# TLSR826X register map
File version: 0.1
Registers are 8-bit, access not given, no defined reset value unless marked. A register's access mark holds for its fields unless they carry their own. Offsets are from the block's base; [hi:lo] are bit positions; {n}, {i} and the like mark numbered series.

## AUDIO — Auto-generated from section 'audio'
Base 0x00800056
0x00 AUD_CONST 32-bit — Auto-generated from aud_const
0xAA CTRL_EP_PTR — Auto-generated from ctrl_ep_ptr
0xAB CTRL_EP_DAT — Auto-generated from ctrl_ep_dat
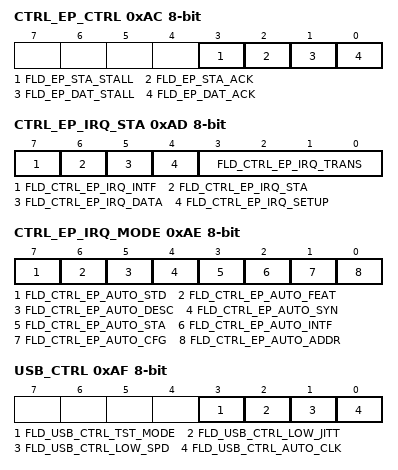
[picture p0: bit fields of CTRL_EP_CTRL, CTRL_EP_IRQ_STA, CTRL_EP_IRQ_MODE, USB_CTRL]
0xAC CTRL_EP_CTRL — Auto-generated from ctrl_ep_ctrl
  [3] FLD_EP_STA_STALL, [2] FLD_EP_STA_ACK, [1] FLD_EP_DAT_STALL, [0] FLD_EP_DAT_ACK
0xAD CTRL_EP_IRQ_STA — Auto-generated from ctrl_ep_irq_sta
  [7] FLD_CTRL_EP_IRQ_INTF, [6] FLD_CTRL_EP_IRQ_STA, [5] FLD_CTRL_EP_IRQ_DATA, [4] FLD_CTRL_EP_IRQ_SETUP, [3:0] FLD_CTRL_EP_IRQ_TRANS
0xAE CTRL_EP_IRQ_MODE — Auto-generated from ctrl_ep_irq_mode
  [7] FLD_CTRL_EP_AUTO_STD, [6] FLD_CTRL_EP_AUTO_FEAT, [5] FLD_CTRL_EP_AUTO_DESC, [4] FLD_CTRL_EP_AUTO_SYN, [3] FLD_CTRL_EP_AUTO_STA, [2] FLD_CTRL_EP_AUTO_INTF, [1] FLD_CTRL_EP_AUTO_CFG, [0] FLD_CTRL_EP_AUTO_ADDR
0xAF USB_CTRL — Auto-generated from usb_ctrl
  [3] FLD_USB_CTRL_TST_MODE, [2] FLD_USB_CTRL_LOW_JITT, [1] FLD_USB_CTRL_LOW_SPD, [0] FLD_USB_CTRL_AUTO_CLK
0xB0 USB_CYC_CALI 16-bit — Auto-generated from usb_cyc_cali
0xB4 USB_MDEV — Auto-generated from usb_mdev
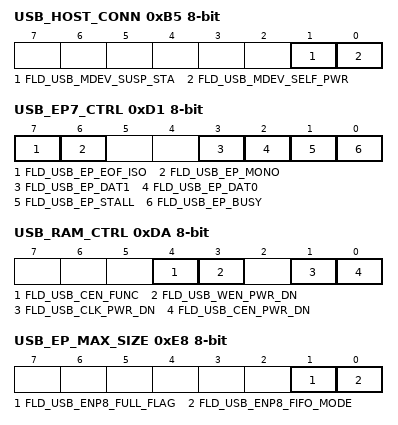
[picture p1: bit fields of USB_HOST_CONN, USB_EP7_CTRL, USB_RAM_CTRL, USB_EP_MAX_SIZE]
0xB5 USB_HOST_CONN — Auto-generated from usb_host_conn
  [1] FLD_USB_MDEV_SUSP_STA, [0] FLD_USB_MDEV_SELF_PWR
0xB6 USB_SUPS_CYC_CALI — Auto-generated from usb_sups_cyc_cali
0xB7 USB_INTF_ALT — Auto-generated from usb_intf_alt
0xBA USB_EP8123_PTR 32-bit — Auto-generated from usb_ep8123_ptr; aliases: USB_EP8_PTR
{0xBA+i} USB_EP{i}_PTR (i=1..3) — Auto-generated from usb_ep{i}_ptr
0xBE USB_EP4567_PTR 32-bit — Auto-generated from usb_ep4567_ptr; aliases: USB_EP4_PTR
{0xBA+i} USB_EP{i}_PTR (i=5..7) — Auto-generated from usb_ep{i}_ptr
0xC2 USB_EP8123_DAT 32-bit — Auto-generated from usb_ep8123_dat; aliases: USB_EP8_DAT
{0xC2+i} USB_EP{i}_DAT (i=1..3) — Auto-generated from usb_ep{i}_dat
0xC6 USB_EP4567_DAT 32-bit — Auto-generated from usb_ep4567_dat; aliases: USB_EP4_DAT
{0xC2+i} USB_EP{i}_DAT (i=5..7) — Auto-generated from usb_ep{i}_dat
0xCA USB_EP8_CTRL — Auto-generated from usb_ep8_ctrl
{0xCA+i} USB_EP{i}_CTRL (i=1..6) — Auto-generated from usb_ep{i}_ctrl
0xD1 USB_EP7_CTRL — Auto-generated from usb_ep7_ctrl
  [7] FLD_USB_EP_EOF_ISO, [6] FLD_USB_EP_MONO, [3] FLD_USB_EP_DAT1, [2] FLD_USB_EP_DAT0, [1] FLD_USB_EP_STALL, [0] FLD_USB_EP_BUSY
0xD2 USB_EP8123_BUF_ADDR 32-bit — Auto-generated from usb_ep8123_buf_addr; aliases: USB_EP8_BUF_ADDR
{0xD2+i} USB_EP{i}_BUF_ADDR (i=1..3) — Auto-generated from usb_ep{i}_buf_addr
0xD6 USB_EP4567_BUF_ADDR 32-bit — Auto-generated from usb_ep4567_buf_addr; aliases: USB_EP4_BUF_ADDR
{0xD2+i} USB_EP{i}_BUF_ADDR (i=5..7) — Auto-generated from usb_ep{i}_buf_addr
0xDA USB_RAM_CTRL — Auto-generated from usb_ram_ctrl
  [4] FLD_USB_CEN_FUNC, [3] FLD_USB_WEN_PWR_DN, [1] FLD_USB_CLK_PWR_DN, [0] FLD_USB_CEN_PWR_DN
0xE2 USB_ISO_MODE — Auto-generated from usb_iso_mode
0xE3 USB_IRQ — Auto-generated from usb_irq
0xE4 USB_MASK — Auto-generated from usb_mask
0xE5 USB_EP8_SEND_MAX — Auto-generated from usb_ep8_send_max
0xE6 USB_EP8_SEND_THRES — Auto-generated from usb_ep8_send_thres
0xE7 USB_EP8_FIFO_MODE — Auto-generated from usb_ep8_fifo_mode
0xE8 USB_EP_MAX_SIZE — Auto-generated from usb_ep_max_size
  [1] FLD_USB_ENP8_FULL_FLAG, [0] FLD_USB_ENP8_FIFO_MODE
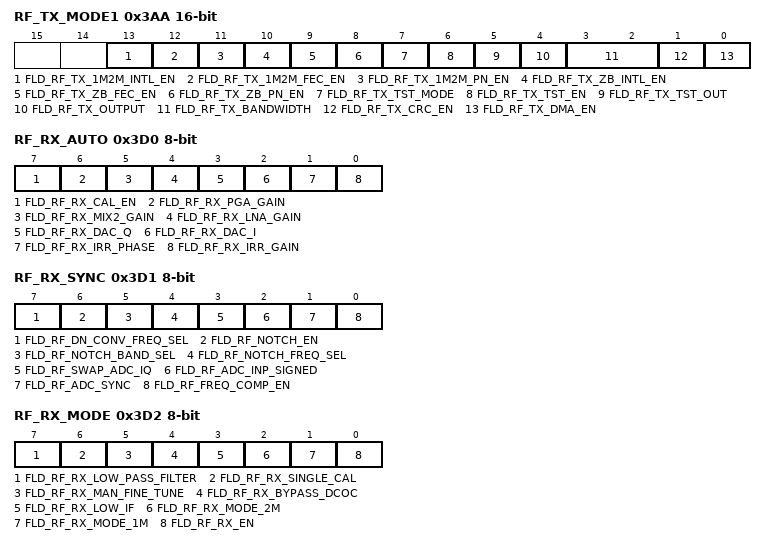
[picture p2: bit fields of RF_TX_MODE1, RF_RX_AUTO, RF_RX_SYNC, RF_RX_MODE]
0x3AA RF_TX_MODE1 16-bit — Auto-generated from rf_tx_mode1; aliases: RF_TX_MODE
  [13] FLD_RF_TX_1M2M_INTL_EN, [12] FLD_RF_TX_1M2M_FEC_EN, [11] FLD_RF_TX_1M2M_PN_EN, [10] FLD_RF_TX_ZB_INTL_EN, [9] FLD_RF_TX_ZB_FEC_EN, [8] FLD_RF_TX_ZB_PN_EN, [7] FLD_RF_TX_TST_MODE, [6] FLD_RF_TX_TST_EN, [5] FLD_RF_TX_TST_OUT, [4] FLD_RF_TX_OUTPUT, [3:2] FLD_RF_TX_BANDWIDTH, [1] FLD_RF_TX_CRC_EN, [0] FLD_RF_TX_DMA_EN
0x3C6 RF_TX_BUF_STA 32-bit — Auto-generated from rf_tx_buf_sta
0x3CC RF_RX_SENSE_THR — Auto-generated from rf_rx_sense_thr
0x3D0 RF_RX_AUTO — Auto-generated from rf_rx_auto
  [7] FLD_RF_RX_CAL_EN, [6] FLD_RF_RX_PGA_GAIN, [5] FLD_RF_RX_MIX2_GAIN, [4] FLD_RF_RX_LNA_GAIN, [3] FLD_RF_RX_DAC_Q, [2] FLD_RF_RX_DAC_I, [1] FLD_RF_RX_IRR_PHASE, [0] FLD_RF_RX_IRR_GAIN
0x3D1 RF_RX_SYNC — Auto-generated from rf_rx_sync
  [7] FLD_RF_DN_CONV_FREQ_SEL, [6] FLD_RF_NOTCH_EN, [5] FLD_RF_NOTCH_BAND_SEL, [4] FLD_RF_NOTCH_FREQ_SEL, [3] FLD_RF_SWAP_ADC_IQ, [2] FLD_RF_ADC_INP_SIGNED, [1] FLD_RF_ADC_SYNC, [0] FLD_RF_FREQ_COMP_EN
0x3D2 RF_RX_MODE — Auto-generated from rf_rx_mode
  [7] FLD_RF_RX_LOW_PASS_FILTER, [6] FLD_RF_RX_SINGLE_CAL, [5] FLD_RF_RX_MAN_FINE_TUNE, [4] FLD_RF_RX_BYPASS_DCOC, [3] FLD_RF_RX_LOW_IF, [2] FLD_RF_RX_MODE_2M, [1] FLD_RF_RX_MODE_1M, [0] FLD_RF_RX_EN
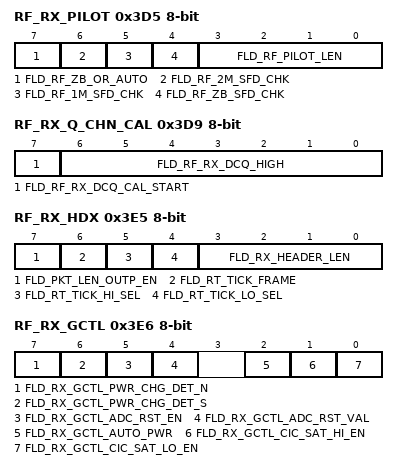
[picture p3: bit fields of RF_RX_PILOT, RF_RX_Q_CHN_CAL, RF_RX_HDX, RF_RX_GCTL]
0x3D5 RF_RX_PILOT — Auto-generated from rf_rx_pilot
  [7] FLD_RF_ZB_OR_AUTO, [6] FLD_RF_2M_SFD_CHK, [5] FLD_RF_1M_SFD_CHK, [4] FLD_RF_ZB_SFD_CHK, [3:0] FLD_RF_PILOT_LEN
0x3D6 RF_RX_CHN_DC 32-bit — Auto-generated from rf_rx_chn_dc
0x3D9 RF_RX_Q_CHN_CAL — Auto-generated from rf_rx_q_chn_cal
  [7] FLD_RF_RX_DCQ_CAL_START, [6:0] FLD_RF_RX_DCQ_HIGH
0x3DE RF_RX_PEL 32-bit — Auto-generated from rf_rx_pel; aliases: RF_RX_PEL_GAIN
0x3E3 RF_RX_RSSI_OFFSET — Auto-generated from rf_rx_rssi_offset
0x3E5 RF_RX_HDX — Auto-generated from rf_rx_hdx
  [7] FLD_PKT_LEN_OUTP_EN, [6] FLD_RT_TICK_FRAME, [5] FLD_RT_TICK_HI_SEL, [4] FLD_RT_TICK_LO_SEL, [3:0] FLD_RX_HEADER_LEN
0x3E6 RF_RX_GCTL — Auto-generated from rf_rx_gctl
  [7] FLD_RX_GCTL_PWR_CHG_DET_N, [6] FLD_RX_GCTL_PWR_CHG_DET_S, [5] FLD_RX_GCTL_ADC_RST_EN, [4] FLD_RX_GCTL_ADC_RST_VAL, [2] FLD_RX_GCTL_AUTO_PWR, [1] FLD_RX_GCTL_CIC_SAT_HI_EN, [0] FLD_RX_GCTL_CIC_SAT_LO_EN
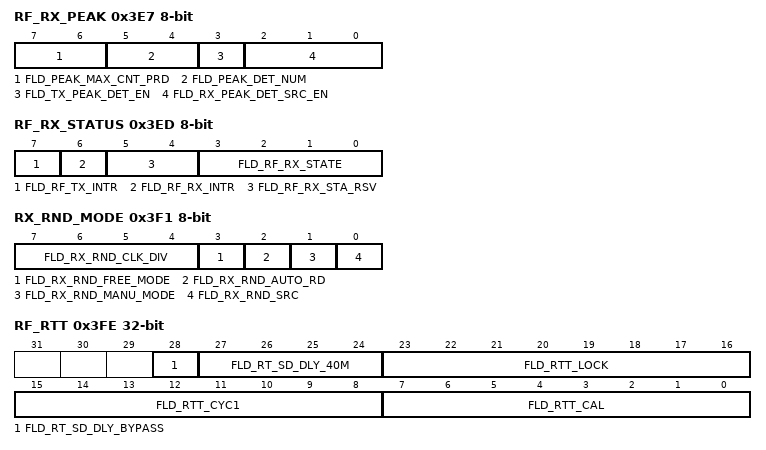
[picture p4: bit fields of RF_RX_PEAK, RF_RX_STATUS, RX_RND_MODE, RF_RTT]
0x3E7 RF_RX_PEAK — Auto-generated from rf_rx_peak
  [7:6] FLD_PEAK_MAX_CNT_PRD, [5:4] FLD_PEAK_DET_NUM, [3] FLD_TX_PEAK_DET_EN, [2:0] FLD_RX_PEAK_DET_SRC_EN
0x3ED RF_RX_STATUS — Auto-generated from rf_rx_status
  [7] FLD_RF_TX_INTR, [6] FLD_RF_RX_INTR, [5:4] FLD_RF_RX_STA_RSV, [3:0] FLD_RF_RX_STATE
0x3F1 RX_RND_MODE — Auto-generated from rx_rnd_mode
  [7:4] FLD_RX_RND_CLK_DIV, [3] FLD_RX_RND_FREE_MODE, [2] FLD_RX_RND_AUTO_RD, [1] FLD_RX_RND_MANU_MODE, [0] FLD_RX_RND_SRC
0x3F2 RND_NUMBER 16-bit — Auto-generated from rnd_number
0x3F6 BB_MAX_TICK 16-bit — Auto-generated from bb_max_tick
0x3FE RF_RTT 32-bit — Auto-generated from rf_rtt
  [28] FLD_RT_SD_DLY_BYPASS, [27:24] FLD_RT_SD_DLY_40M, [23:16] FLD_RTT_LOCK, [15:8] FLD_RTT_CYC1, [7:0] FLD_RTT_CAL
0x402 RF_CHN_RSSI — Auto-generated from rf_chn_rssi
0x47A PLL_RX_COARSE_TUNE 16-bit — Auto-generated from pll_rx_coarse_tune
0x47C PLL_RX_COARSE_DIV — Auto-generated from pll_rx_coarse_div
0x47E PLL_RX_FINE_TUNE 16-bit — Auto-generated from pll_rx_fine_tune
0x480 PLL_RX_FINE_DIV — Auto-generated from pll_rx_fine_div
0x482 PLL_TX_COARSE_TUNE 16-bit — Auto-generated from pll_tx_coarse_tune
0x484 PLL_TX_COARSE_DIV — Auto-generated from pll_tx_coarse_div
0x486 PLL_TX_FINE_TUNE 16-bit — Auto-generated from pll_tx_fine_tune
0x488 PLL_TX_FINE_DIV — Auto-generated from pll_tx_fine_div
0x48A PLL_RX_FRAC 32-bit — Auto-generated from pll_rx_frac
0x48E PLL_TX_FRAC 32-bit — Auto-generated from pll_tx_frac
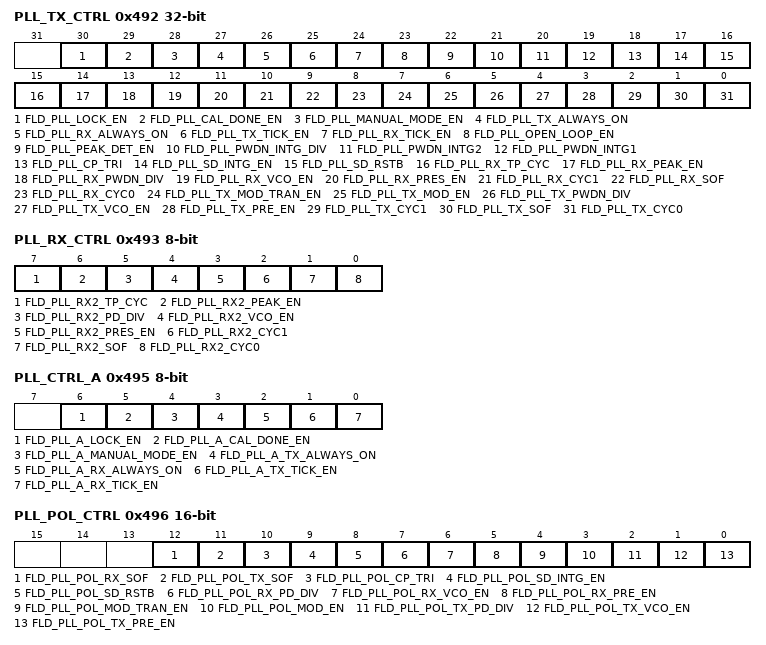
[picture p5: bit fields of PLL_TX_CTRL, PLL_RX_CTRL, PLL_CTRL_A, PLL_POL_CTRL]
0x492 PLL_TX_CTRL 32-bit — Auto-generated from pll_tx_ctrl; aliases: PLL_CTRL, PLL_CTRL16
  [30] FLD_PLL_LOCK_EN, [29] FLD_PLL_CAL_DONE_EN, [28] FLD_PLL_MANUAL_MODE_EN, [27] FLD_PLL_TX_ALWAYS_ON, [26] FLD_PLL_RX_ALWAYS_ON, [25] FLD_PLL_TX_TICK_EN, [24] FLD_PLL_RX_TICK_EN, [23] FLD_PLL_OPEN_LOOP_EN, [22] FLD_PLL_PEAK_DET_EN, [21] FLD_PLL_PWDN_INTG_DIV, [20] FLD_PLL_PWDN_INTG2, [19] FLD_PLL_PWDN_INTG1, [18] FLD_PLL_CP_TRI, [17] FLD_PLL_SD_INTG_EN, [16] FLD_PLL_SD_RSTB, [15] FLD_PLL_RX_TP_CYC, [14] FLD_PLL_RX_PEAK_EN, [13] FLD_PLL_RX_PWDN_DIV, [12] FLD_PLL_RX_VCO_EN, [11] FLD_PLL_RX_PRES_EN, [10] FLD_PLL_RX_CYC1, [9] FLD_PLL_RX_SOF, [8] FLD_PLL_RX_CYC0, [7] FLD_PLL_TX_MOD_TRAN_EN, [6] FLD_PLL_TX_MOD_EN, [5] FLD_PLL_TX_PWDN_DIV, [4] FLD_PLL_TX_VCO_EN, [3] FLD_PLL_TX_PRE_EN, [2] FLD_PLL_TX_CYC1, [1] FLD_PLL_TX_SOF, [0] FLD_PLL_TX_CYC0
0x493 PLL_RX_CTRL — Auto-generated from pll_rx_ctrl
  [7] FLD_PLL_RX2_TP_CYC, [6] FLD_PLL_RX2_PEAK_EN, [5] FLD_PLL_RX2_PD_DIV, [4] FLD_PLL_RX2_VCO_EN, [3] FLD_PLL_RX2_PRES_EN, [2] FLD_PLL_RX2_CYC1, [1] FLD_PLL_RX2_SOF, [0] FLD_PLL_RX2_CYC0
0x495 PLL_CTRL_A — Auto-generated from pll_ctrl_a
  [6] FLD_PLL_A_LOCK_EN, [5] FLD_PLL_A_CAL_DONE_EN, [4] FLD_PLL_A_MANUAL_MODE_EN, [3] FLD_PLL_A_TX_ALWAYS_ON, [2] FLD_PLL_A_RX_ALWAYS_ON, [1] FLD_PLL_A_TX_TICK_EN, [0] FLD_PLL_A_RX_TICK_EN
0x496 PLL_POL_CTRL 16-bit — Auto-generated from pll_pol_ctrl
  [12] FLD_PLL_POL_RX_SOF, [11] FLD_PLL_POL_TX_SOF, [10] FLD_PLL_POL_CP_TRI, [9] FLD_PLL_POL_SD_INTG_EN, [8] FLD_PLL_POL_SD_RSTB, [7] FLD_PLL_POL_RX_PD_DIV, [6] FLD_PLL_POL_RX_VCO_EN, [5] FLD_PLL_POL_RX_PRE_EN, [4] FLD_PLL_POL_MOD_TRAN_EN, [3] FLD_PLL_POL_MOD_EN, [2] FLD_PLL_POL_TX_PD_DIV, [1] FLD_PLL_POL_TX_VCO_EN, [0] FLD_PLL_POL_TX_PRE_EN
0x49A RF_RX_CAP 16-bit — Auto-generated from rf_rx_cap; aliases: RF_TX_CAP
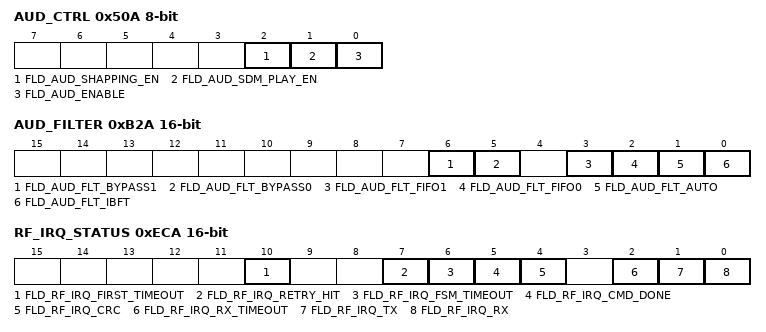
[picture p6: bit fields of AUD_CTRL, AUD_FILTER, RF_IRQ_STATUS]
0x50A AUD_CTRL — Auto-generated from aud_ctrl
  [2] FLD_AUD_SHAPPING_EN, [1] FLD_AUD_SDM_PLAY_EN, [0] FLD_AUD_ENABLE
0x50B AUD_VOL_CTRL — Auto-generated from aud_vol_ctrl
0x50C AUD_PN1 — Auto-generated from aud_pn1
0x50D AUD_PN2 — Auto-generated from aud_pn2
0x50E ASCL_STEP 16-bit — Auto-generated from ascl_step
0x512 AUD_BASE_ADR 16-bit — Auto-generated from aud_base_adr
0x514 AUD_BUFF_SIZE — Auto-generated from aud_buff_size
0x516 AUD_RPTR 16-bit — Auto-generated from aud_rptr
0xB2A AUD_FILTER 16-bit — Auto-generated from aud_filter
  [6] FLD_AUD_FLT_BYPASS1, [5] FLD_AUD_FLT_BYPASS0, [3] FLD_AUD_FLT_FIFO1, [2] FLD_AUD_FLT_FIFO0, [1] FLD_AUD_FLT_AUTO, [0] FLD_AUD_FLT_IBFT
0xB2B AUD_SRAM — Auto-generated from aud_sram
0xEC6 RF_IRQ_MASK 16-bit — Auto-generated from rf_irq_mask
0xECA RF_IRQ_STATUS 16-bit — Auto-generated from rf_irq_status
  [10] FLD_RF_IRQ_FIRST_TIMEOUT, [7] FLD_RF_IRQ_RETRY_HIT, [6] FLD_RF_IRQ_FSM_TIMEOUT, [5] FLD_RF_IRQ_CMD_DONE, [4] FLD_RF_IRQ_CRC, [2] FLD_RF_IRQ_RX_TIMEOUT, [1] FLD_RF_IRQ_TX, [0] FLD_RF_IRQ_RX
